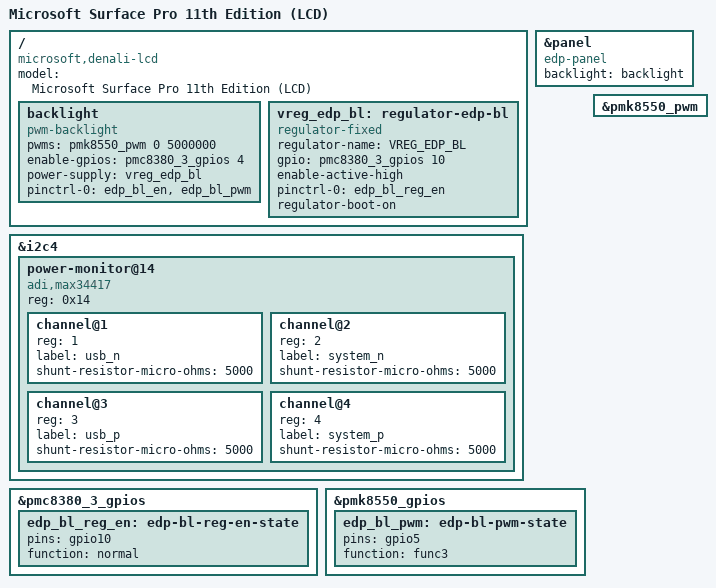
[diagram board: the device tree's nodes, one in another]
// SPDX-License-Identifier: BSD-3-Clause
/*
 * Copyright (c) 2025 Dale Whinham <daleyo@gmail.com>
 */

/dts-v1/;

#include "x1p64100.dtsi"
#include "x1-microsoft-denali.dtsi"

/ {
	model = "Microsoft Surface Pro 11th Edition (LCD)";
	compatible = "microsoft,denali-lcd", "microsoft,denali",
		     "qcom,x1p64100", "qcom,x1e80100";

	backlight: backlight {
		compatible = "pwm-backlight";
		pwms = <&pmk8550_pwm 0 5000000>;
		enable-gpios = <&pmc8380_3_gpios 4 GPIO_ACTIVE_HIGH>;
		power-supply = <&vreg_edp_bl>;

		pinctrl-0 = <&edp_bl_en>, <&edp_bl_pwm>;
		pinctrl-names = "default";
	};

	vreg_edp_bl: regulator-edp-bl {
		compatible = "regulator-fixed";

		regulator-name = "VREG_EDP_BL";

		gpio = <&pmc8380_3_gpios 10 GPIO_ACTIVE_HIGH>;
		enable-active-high;

		pinctrl-0 = <&edp_bl_reg_en>;
		pinctrl-names = "default";

		regulator-boot-on;
	};
};

&i2c4 {
	/* Rails as named by the firmware's power meter description */
	power-monitor@14 {
		compatible = "adi,max34417";
		reg = <0x14>;
		#address-cells = <1>;
		#size-cells = <0>;

		channel@1 {
			reg = <1>;
			label = "usb_n";
			shunt-resistor-micro-ohms = <5000>;
		};

		channel@2 {
			reg = <2>;
			label = "system_n";
			shunt-resistor-micro-ohms = <5000>;
		};

		channel@3 {
			reg = <3>;
			label = "usb_p";
			shunt-resistor-micro-ohms = <5000>;
		};

		channel@4 {
			reg = <4>;
			label = "system_p";
			shunt-resistor-micro-ohms = <5000>;
		};
	};
};

&panel {
	compatible = "edp-panel";
	backlight = <&backlight>;
};

&pmc8380_3_gpios {
	edp_bl_reg_en: edp-bl-reg-en-state {
		pins = "gpio10";
		function = "normal";
	};
};

&pmk8550_gpios {
	edp_bl_pwm: edp-bl-pwm-state {
		pins = "gpio5";
		function = "func3";
	};
};

&pmk8550_pwm {
	status = "okay";
};
